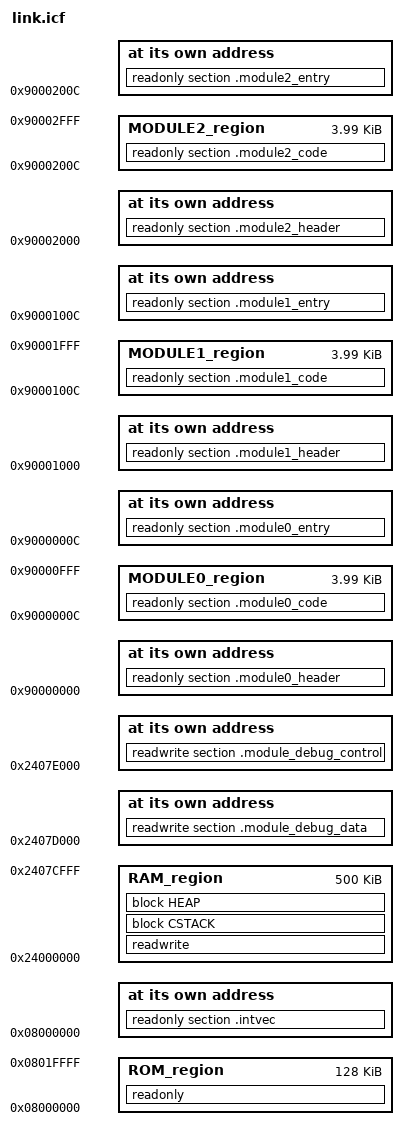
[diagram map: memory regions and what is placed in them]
/* IAR linker configuration for STM32H750 Ethernet-only RT-Thread image.
 * Minimal Ethernet/LwIP image executes directly from internal flash. */

define symbol __ICFEDIT_intvec_start__ = 0x08000000;
define symbol __ICFEDIT_region_ROM_start__ = 0x08000000;
define symbol __ICFEDIT_region_ROM_end__   = 0x0801FFFF;
define symbol __ICFEDIT_region_RAM_start__ = 0x24000000;
/*
 * Модули исполняются из W25Q128 через окно 0x90000000.
 * 0x2407D000..0x2407EFFF зарезервировано под загрузку W25Q128 через J-Link.
 * Верхняя страница AXI SRAM 0x2407F000 зарезервирована под API модулей.
 */
define symbol __ICFEDIT_region_RAM_end__   = 0x2407CFFF;

define memory mem with size = 4G;
define region ROM_region = mem:[from __ICFEDIT_region_ROM_start__
                                to __ICFEDIT_region_ROM_end__];
define region RAM_region = mem:[from __ICFEDIT_region_RAM_start__
                                to __ICFEDIT_region_RAM_end__];
define region MODULE0_region = mem:[from 0x9000000C to 0x90000FFF];
define region MODULE1_region = mem:[from 0x9000100C to 0x90001FFF];
define region MODULE2_region = mem:[from 0x9000200C to 0x90002FFF];

define block CSTACK with alignment = 8, size = 0x1000 { };
define block HEAP   with alignment = 8, size = 0x1000 { };

initialize by copy { readwrite };
do not initialize { section .noinit };

place at address mem:__ICFEDIT_intvec_start__ { readonly section .intvec };
place at address mem:0x2407D000 { readwrite section .module_debug_data };
place at address mem:0x2407E000 { readwrite section .module_debug_control };
place at address mem:0x90000000 { readonly section .module0_header };
place at address mem:0x9000000C { readonly section .module0_entry };
place in MODULE0_region { readonly section .module0_code };
place at address mem:0x90001000 { readonly section .module1_header };
place at address mem:0x9000100C { readonly section .module1_entry };
place in MODULE1_region { readonly section .module1_code };
place at address mem:0x90002000 { readonly section .module2_header };
place at address mem:0x9000200C { readonly section .module2_entry };
place in MODULE2_region { readonly section .module2_code };
place in ROM_region { readonly };
place in RAM_region { readwrite, block CSTACK, block HEAP };
